# AVR32SD20 register map
Vendor: Atmel; File version: 1.0
CPU: other r0p0, little endian, no MPU, no FPU, 4 interrupt priority bits
Registers are 8-bit, read-write, reset 0x0 unless marked. A register's access mark holds for its fields unless they carry their own. Offsets are from the block's base; [hi:lo] are bit positions; {n}, {i} and the like mark numbered series.

## SPI0 — Serial Peripheral Interface
Base 0x00800940
Same registers: SPI1 0x00800960
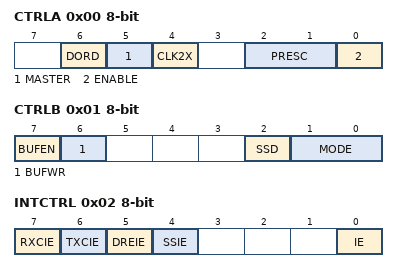
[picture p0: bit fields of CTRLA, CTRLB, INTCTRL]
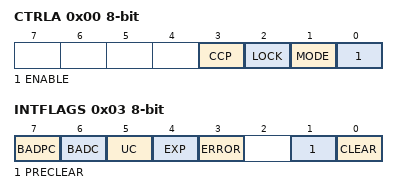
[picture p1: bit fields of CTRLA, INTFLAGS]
0x00 CTRLA — Control A
  [6] DORD — Data Order Setting
  [5] MASTER — Host Operation Enable
  [4] CLK2X — Enable Double Speed
  [2:1] PRESC — Prescaler
    0=DIV4 (CLK_PER / 4); 1=DIV16 (CLK_PER / 16); 2=DIV64 (CLK_PER / 64); 3=DIV128 (CLK_PER / 128)
  [0] ENABLE — Enable Module
0x01 CTRLB — Control B
  [7] BUFEN — Buffer Mode Enable
  [6] BUFWR — Buffer Mode Wait for Receive
  [2] SSD — SPI Select Disable
  [1:0] MODE — SPI Mode
    {v}=SPI Mode {v} (v=0..3)
0x02 INTCTRL — Interrupt Control
  [7] RXCIE — Receive Complete Interrupt Enable
  [6] TXCIE — Transfer Complete Interrupt Enable
  [5] DREIE — Data Register Empty Interrupt Enable
  [4] SSIE — SPI Select Trigger Interrupt Enable
  [0] IE — Interrupt Enable
0x03 INTFLAGS — Interrupt Flags
  [7] IF — Interrupt Flag
  [7] RXCIF — Receive Complete Interrupt Flag
  [6] TXCIF — Transfer Complete Interrupt Flag
  [6] WRCOL — Write Collision
  [5] DREIF — Data Register Empty Interrupt Flag
  [4] SSIF — SPI Select Trigger Interrupt Flag
  [0] BUFOVF — Buffer Overflow
0x04 DATA

## SWDT — Synchronous Watchdog Timer
Base 0x00800E20
0x00 CTRLA — Control A
  [3] CCP — SWDT Register Lock
  [2] LOCK
    0=UNLOCKED (SWDT SFRs are not LOCK-Protected); 1=LOCKED (SWDT SFRs are LOCK-Protected)
  [1] MODE — Peripheral Mode
    0=CLOCK (SWDT counts clock cycles); 1=INSTRUCTION (SWDT counts executed instructions)
  [0] ENABLE — Peripheral Enable
0x01 CTRLB wo — Control B
  [0] TEST
0x02 INTCTRL — Interrupt Control
  [3] ERROR — SWDT Error interrupt enable
0x03 INTFLAGS — Interrupt Flags
  [7] BADPC ro — Non-PRECLEAR Command received while expecting PRECLEAR
  [6] BADC ro — Non-CLEAR Command received while expecting CLEAR
  [5] UC ro — Unexpected Command
  [4] EXP ro — Counter has expired
  [3] ERROR — SWDT Error has occured
  [1] PRECLEAR ro — Preclear Ready
  [0] CLEAR ro — Clear Ready
0x04 CNT 32-bit ro (reset mask 0xFF) — Counter
  [23:0] CNT — SWDT Counter
0x08 RESET 32-bit (reset mask 0xFF) — Counter Reset
  [23:0] RESET — SWDT Counter Reset Value
0x0C WINDOW 16-bit (reset mask 0xFF) — Counter Window
0x0E COMMAND wo
  [7:0] COMMAND — SWDT Command
    8=PRECLEAR (Step 1 in the SWDT clear sequence); 16=CLEAR (Step 2 in the SWDT clear sequence)

## SYSCFG — System Configuration Registers
Base 0x00800F01
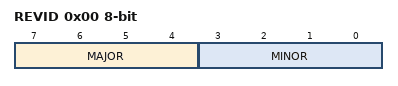
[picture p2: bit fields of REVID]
0x00 REVID ro — Revision ID
  [7:4] MAJOR — Major Revision
  [3:0] MINOR — Minor Revision

## TCB0 — 16-bit Timer Type B
Base 0x00800B00
Same registers: TCB1 0x00800B10, TCB2 0x00800B20, TCB3 0x00800B30
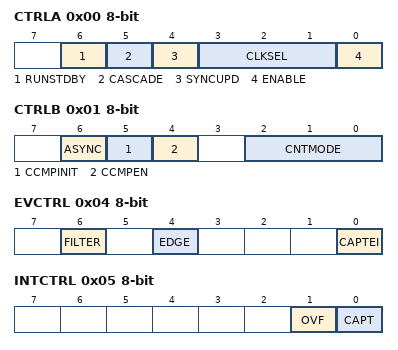
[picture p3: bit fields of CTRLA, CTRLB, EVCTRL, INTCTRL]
0x00 CTRLA — Control A
  [6] RUNSTDBY — Run Standby
  [5] CASCADE — Cascade two timers
  [4] SYNCUPD — Synchronize Update
  [3:1] CLKSEL — Clock Select
    0=DIV1 (CLK_PER); 1=DIV2 (CLK_PER/2); 2=TCA0 (Use CLK_TCA from TCA0); 7=EVENT (Count on event edge)
  [0] ENABLE
0x01 CTRLB — Control Register B
  [6] ASYNC — Asynchronous Enable
  [5] CCMPINIT — Pin Initial State
  [4] CCMPEN — Pin Output Enable
  [2:0] CNTMODE — Timer Mode
    0=INT (Periodic Interrupt); 1=TIMEOUT (Periodic Timeout); 2=CAPT (Input Capture Event); 3=FRQ (Input Capture Frequency measurement); 4=PW (Input Capture Pulse-Width measurement); 5=FRQPW (Input Capture Frequency and Pulse-Width measurement); 6=SINGLE (Single Shot); 7=PWM8 (8-bit PWM)
0x04 EVCTRL — Event Control
  [6] FILTER — Input Capture Noise Cancellation Filter
  [4] EDGE — Event Edge
  [0] CAPTEI — Event Input Enable
0x05 INTCTRL — Interrupt Control
  [1] OVF — Overflow
  [0] CAPT — Capture or Timeout
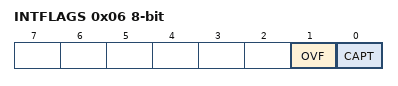
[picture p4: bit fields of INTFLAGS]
0x06 INTFLAGS — Interrupt Flags
  [1] OVF — Overflow
  [0] CAPT — Capture or Timeout
0x07 STATUS ro
  [0] RUN
0x08 DBGCTRL — Debug Control
  [0] DBGRUN — Debug Run
0x09 TEMP — Temporary Value
0x0A CNT 16-bit (reset mask 0xFF) — Count
0x0C CCMP 16-bit (reset mask 0xFF) — Compare or Capture
